# PIC32CZ4010CA80144 device description
Architecture: CORTEX-M7; Family: PIC32C; Series: PIC32CZCA80
Registers are 32-bit, read-write, reset 0x0 unless marked. A register's access mark holds for its fields unless they carry their own. Offsets are from the block's base; [hi:lo] are bit positions; {n}, {i} and the like mark numbered series; <NAME> marks a mode.

## FPU — Floating Point Unit
Instances: FPU 0xE000EF30
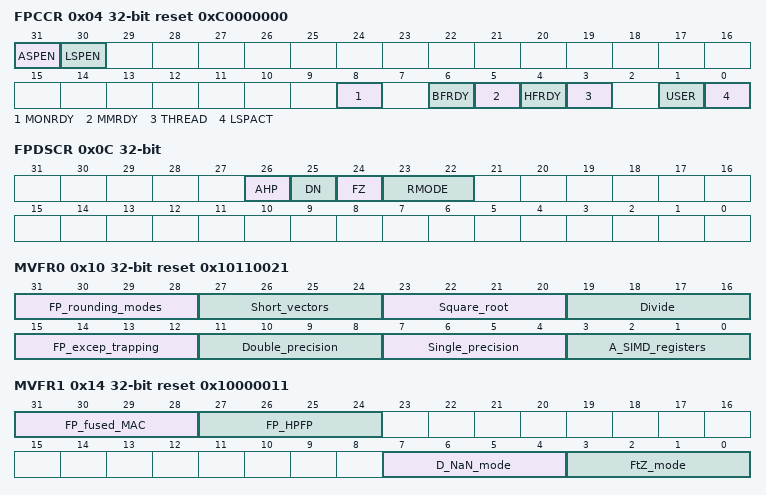
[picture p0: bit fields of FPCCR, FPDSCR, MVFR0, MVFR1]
0x04 FPCCR reset 0xC0000000 — Floating-Point Context Control Register
  [31] ASPEN, [30] LSPEN, [8] MONRDY, [6] BFRDY, [5] MMRDY, [4] HFRDY, [3] THREAD, [1] USER, [0] LSPACT
0x08 FPCAR reset not defined — Floating-Point Context Address Register
  [31:3] ADDRESS — Address for FP registers in exception stack frame
0x0C FPDSCR — Floating-Point Default Status Control Register
  [26] AHP — Default value for FPSCR.AHP
  [25] DN — Default value for FPSCR.DN
  [24] FZ — Default value for FPSCR.FZ
  [23:22] RMODE — Default value for FPSCR.RMODE
    0=RN (Round to Nearest); 1=RP (Round towards Positive Infinity); 2=RM (Round towards Negative Infinity); 3=RZ (Round towards Zero)
0x10 MVFR0 ro reset 0x10110021 — Media and FP Feature Register 0
  [31:28] FP_rounding_modes, [27:24] Short_vectors, [23:20] Square_root, [19:16] Divide, [15:12] FP_excep_trapping, [11:8] Double_precision, [7:4] Single_precision, [3:0] A_SIMD_registers
0x14 MVFR1 ro reset 0x10000011 — Media and FP Feature Register 1
  [31:28] FP_fused_MAC, [27:24] FP_HPFP, [7:4] D_NaN_mode, [3:0] FtZ_mode
0x18 MVFR2 ro reset 0x40 — Media and FP Feature Register 2

## FREQM — Frequency Meter
Instances: FREQM 0x44060000
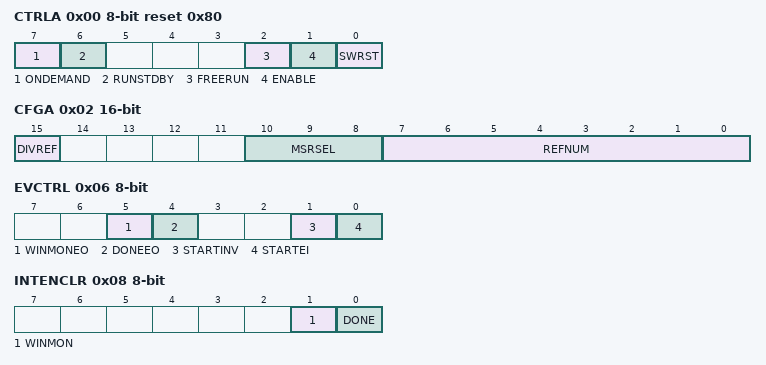
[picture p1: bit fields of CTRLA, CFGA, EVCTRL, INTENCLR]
0x00 CTRLA 8-bit reset 0x80 — Control A Register
  [7] ONDEMAND — On Demand Control
  [6] RUNSTDBY — Run In Standby
  [2] FREERUN — Free Running Mode
  [1] ENABLE
  [0] SWRST — Software Reset
0x01 CTRLB 8-bit wo — Control B Register
  [0] START — Start Measurement
0x02 CFGA 16-bit — Config A Register
  [15] DIVREF — Divide Reference Clock
    0=DIV1 (The reference clock is divided by 1); 1=DIV8 (The reference clock is divided by 8)
  [10:8] MSRSEL — Measurement Clock Selection
    0=GCLK (GCLK Input Clock); 1=CPU (CPU Input Clock)
  [7:0] REFNUM — Number of Reference Clock Cycles
0x04 CTRLC 8-bit — Control C Register
  [2:0] WINMODE — Window Monitor Mode
    0=DISABLE (No window mode (default)); 1=MODE1 (VALUE > WINLT); 2=MODE2 (VALUE < WINUT); 3=MODE3 (WINLT < VALUE < WINUT); 4=MODE4 (!(WINLT < VALUE < WINUT))
0x06 EVCTRL 8-bit — Event Control Register
  [5] WINMONEO — Window Monitor Event Out
  [4] DONEEO — Measurement Done Event Out
  [1] STARTINV — Start Measurement Event Invert Enable
  [0] STARTEI — Start Measurement Event Input Enable
0x08 INTENCLR 8-bit (atomic clear) — Interrupt Enable Clear Register
  [1] WINMON — Window Monitor Interrupt Disable
  [0] DONE — Measurement Done Interrupt Disable
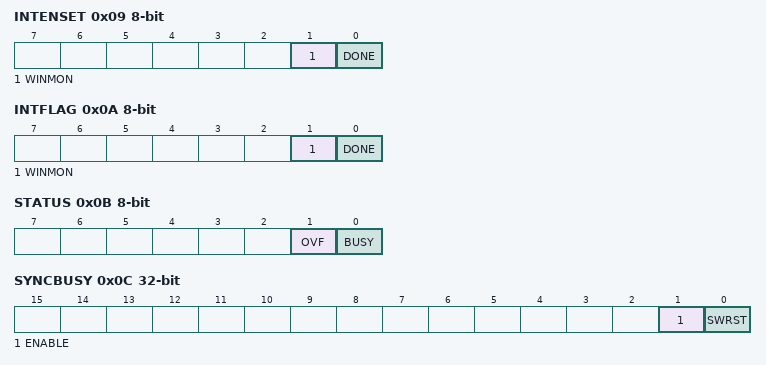
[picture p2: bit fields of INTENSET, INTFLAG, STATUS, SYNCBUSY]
0x09 INTENSET 8-bit (atomic set) — Interrupt Enable Set Register
  [1] WINMON — Window Monitor Interrupt Enable
  [0] DONE — Measurement Done Interrupt Enable
0x0A INTFLAG 8-bit (atomic clear) — Interrupt Flag Register
  [1] WINMON — Window Monitor
  [0] DONE — Measurement Done
0x0B STATUS 8-bit
  [1] OVF — Sticky Count Value Overflow
  [0] BUSY — FREQM Status
0x0C SYNCBUSY ro — Synchronization Busy Register
  [1] ENABLE
  [0] SWRST — Software Reset
0x10 VALUE ro — Count Value Register
  [23:0] VALUE — Measurement Value
0x20 WINLT — Window Monitor Lower Threshold
  [23:0] WINLT — Window Lower Threshold
0x24 WINUT — Window Monitor Upper Threshold
  [23:0] WINUT — Window Upper Threshold

## FUSES_CALOTP — Defines FUSE parameters
Instances: FUSES_CALOTP 0x0A007000
0x180 FCCFG64 ro reset not defined — PTC Calibration
  [15:0] PTCFG0
0x184 FCCFG65 ro reset not defined — ADC Calibration
  [31:0] ADCFG0
0x188 FCCFG66 ro reset not defined — Comparator Calibration
  [7:0] ACPAIR_SEL
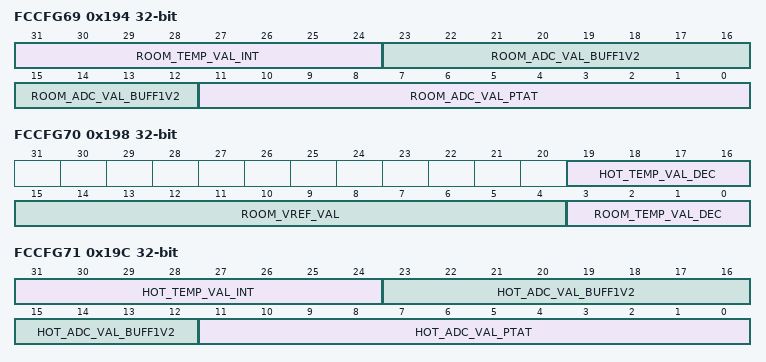
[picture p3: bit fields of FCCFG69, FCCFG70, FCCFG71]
0x194 FCCFG69 ro reset not defined — Temperature calibration values 0
  [31:24] ROOM_TEMP_VAL_INT, [23:12] ROOM_ADC_VAL_BUFF1V2, [11:0] ROOM_ADC_VAL_PTAT
0x198 FCCFG70 ro reset not defined — Temperature calibration values 1
  [19:16] HOT_TEMP_VAL_DEC, [15:4] ROOM_VREF_VAL, [3:0] ROOM_TEMP_VAL_DEC
0x19C FCCFG71 ro reset not defined — Temperature calibration values 2
  [31:24] HOT_TEMP_VAL_INT, [23:12] HOT_ADC_VAL_BUFF1V2, [11:0] HOT_ADC_VAL_PTAT
0x1A0 FCCFG72 ro reset not defined — MAC ID (31 through 0)
  [31:0] FMAC_31_0
0x1A4 FCCFG73 ro reset not defined — MAC ID (47 through 32)
  [15:0] FMAC_47_32
{0x1E0+4i} FCCFG_UNIQID[{i}] (i=0..3) ro reset not defined — Factory programed Unique ID
  [31:0] UID — Unique ID (programmed at factory)
